# M2Sxxx register map
Vendor: Microsemi; Series: SmartFusion2; File version: 2.0.32
CPU: CM3 r2p1, little endian, MPU, no FPU, 4 interrupt priority bits
Registers are 32-bit, read-write, no defined reset value unless marked. A register's access mark holds for its fields unless they carry their own. Offsets are from the block's base; [hi:lo] are bit positions; {n}, {i} and the like mark numbered series.

## HPDMA — No description provided for this peripheral
Base 0x40014000
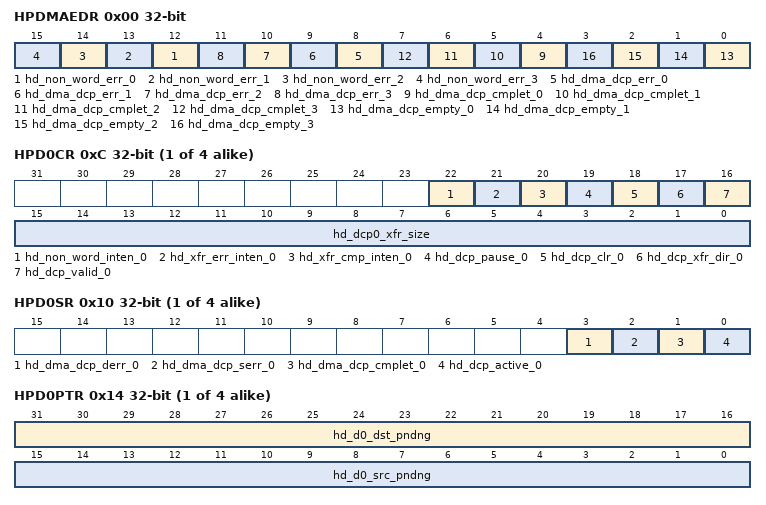
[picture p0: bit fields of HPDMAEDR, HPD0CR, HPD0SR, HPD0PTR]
0x00 HPDMAEDR — No description provided for this register
  [n+12] hd_non_word_err_{n} ro (n=0..3) — No description provided for this field
  [n+8] hd_dma_dcp_err_{n} ro (n=0..3) — No description provided for this field
  [n+4] hd_dma_dcp_cmplet_{n} ro (n=0..3) — No description provided for this field
  [n] hd_dma_dcp_empty_{n} ro (n=0..3) — No description provided for this field
{0x4+0x14*i} HPD{i}SAR (i=0..3) — No description provided for this register
  [31:0] hd_dcp{i}_src_adrs — No description provided for this field
{0x8+0x14*i} HPD{i}DAR (i=0..3) — No description provided for this register
  [31:0] hd_dcp{i}_dst_adrs — No description provided for this field
{0xC+0x14*i} HPD{i}CR (i=0..3) — No description provided for this register
  [22] hd_non_word_inten_{i} — No description provided for this field
  [21] hd_xfr_err_inten_{i} — No description provided for this field
  [20] hd_xfr_cmp_inten_{i} — No description provided for this field
  [19] hd_dcp_pause_{i} — No description provided for this field
  [18] hd_dcp_clr_{i} — No description provided for this field
  [17] hd_dcp_xfr_dir_{i} — No description provided for this field
  [16] hd_dcp_valid_{i} — No description provided for this field
  [15:0] hd_dcp{i}_xfr_size — No description provided for this field
{0x10+0x14*i} HPD{i}SR (i=0..3) — No description provided for this register
  [3] hd_dma_dcp_derr_{i} ro — No description provided for this field
  [2] hd_dma_dcp_serr_{i} ro — No description provided for this field
  [1] hd_dma_dcp_cmplet_{i} ro — No description provided for this field
  [0] hd_dcp_active_{i} ro — No description provided for this field
{0x14+0x14*i} HPD{i}PTR (i=0..3) — No description provided for this register
  [31:16] hd_d{i}_dst_pndng ro — No description provided for this field
  [15:0] hd_d{i}_src_pndng ro — No description provided for this field
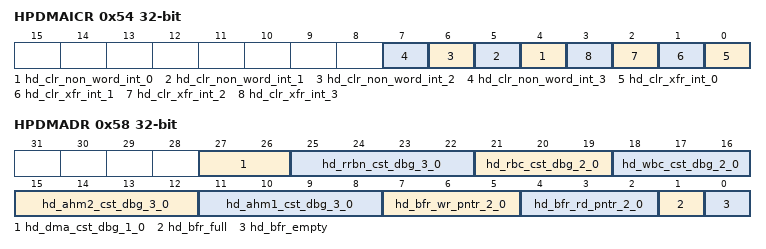
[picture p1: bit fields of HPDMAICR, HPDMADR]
0x54 HPDMAICR — No description provided for this register
  [n+4] hd_clr_non_word_int_{n} wo (n=0..3) — No description provided for this field
  [n] hd_clr_xfr_int_{n} wo (n=0..3) — No description provided for this field
0x58 HPDMADR — No description provided for this register
  [27:26] hd_dma_cst_dbg_1_0 ro — No description provided for this field
  [25:22] hd_rrbn_cst_dbg_3_0 ro — No description provided for this field
  [21:19] hd_rbc_cst_dbg_2_0 ro — No description provided for this field
  [18:16] hd_wbc_cst_dbg_2_0 ro — No description provided for this field
  [15:12] hd_ahm2_cst_dbg_3_0 ro — No description provided for this field
  [11:8] hd_ahm1_cst_dbg_3_0 ro — No description provided for this field
  [7:5] hd_bfr_wr_pntr_2_0 ro — No description provided for this field
  [4:2] hd_bfr_rd_pntr_2_0 ro — No description provided for this field
  [1] hd_bfr_full ro — No description provided for this field
  [0] hd_bfr_empty ro — No description provided for this field

## PDMA — No description provided for this peripheral
Base 0x40003000
0x00 RATIO_HIGH_LOW_Register — No description provided for this register
  [7:0] RATIOHILO — No description provided for this field
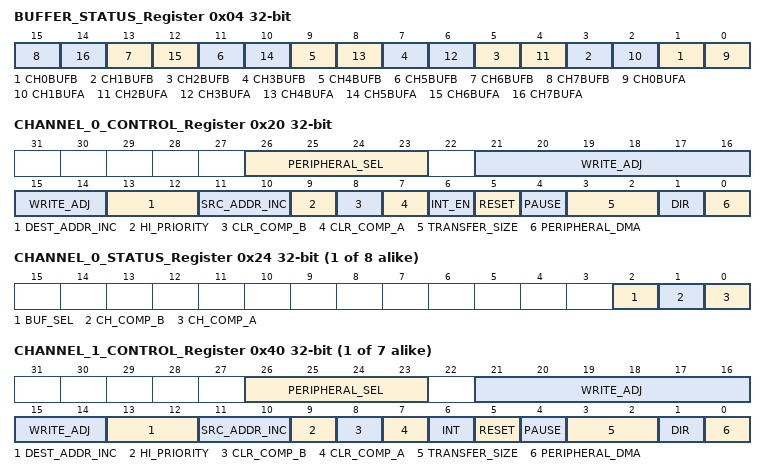
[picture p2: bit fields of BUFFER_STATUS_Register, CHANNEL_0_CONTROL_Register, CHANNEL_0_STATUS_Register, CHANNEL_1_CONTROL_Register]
0x04 BUFFER_STATUS_Register — No description provided for this register
  [2n+1] CH{n}BUFB ro (n=0..7) — No description provided for this field
  [2n] CH{n}BUFA ro (n=0..7) — No description provided for this field
0x20 CHANNEL_0_CONTROL_Register — No description provided for this register
  [26:23] PERIPHERAL_SEL — No description provided for this field
  [21:14] WRITE_ADJ — No description provided for this field
  [13:12] DEST_ADDR_INC — No description provided for this field
  [11:10] SRC_ADDR_INC — No description provided for this field
  [9] HI_PRIORITY — No description provided for this field
  [8] CLR_COMP_B — No description provided for this field
  [7] CLR_COMP_A — No description provided for this field
  [6] INT_EN — No description provided for this field
  [5] RESET — No description provided for this field
  [4] PAUSE — No description provided for this field
  [3:2] TRANSFER_SIZE — No description provided for this field
  [1] DIR — No description provided for this field
  [0] PERIPHERAL_DMA — No description provided for this field
{0x24+0x20*i} CHANNEL_{i}_STATUS_Register (i=0..7) — No description provided for this register
  [2] BUF_SEL ro — No description provided for this field
  [1] CH_COMP_B ro — No description provided for this field
  [0] CH_COMP_A ro — No description provided for this field
{0x28+0x20*i} CHANNEL_{i}_BUFFER_A_SRC_ADDR_Register (i=0..7) — No description provided for this register
  [31:0] BUF_A_SRC — No description provided for this field
{0x2C+0x20*i} CHANNEL_{i}_BUFFER_A_DST_ADDR_Register (i=0..7) — No description provided for this register
  [31:0] BUF_A_DST — No description provided for this field
{0x30+0x20*i} CHANNEL_{i}_BUFFER_A_TRANSFER_COUNT_Register (i=0..7) — No description provided for this register
  [15:0] BUF_A_COUNT — No description provided for this field
{0x34+0x20*i} CHANNEL_{i}_BUFFER_B_SRC_ADDR_Register (i=0..7) — No description provided for this register
  [31:0] BUF_B_SRC — No description provided for this field
{0x38+0x20*i} CHANNEL_{i}_BUFFER_B_DST_ADDR_Register (i=0..7) — No description provided for this register
  [31:0] BUF_B_DST — No description provided for this field
{0x3C+0x20*i} CHANNEL_{i}_BUFFER_B_TRANSFER_COUNT_Register (i=0..7) — No description provided for this register
  [15:0] BUF_B_COUNT — No description provided for this field
{0x20+0x20*i} CHANNEL_{i}_CONTROL_Register (i=1..7) — No description provided for this register
  [26:23] PERIPHERAL_SEL — No description provided for this field
  [21:14] WRITE_ADJ — No description provided for this field
  [13:12] DEST_ADDR_INC — No description provided for this field
  [11:10] SRC_ADDR_INC — No description provided for this field
  [9] HI_PRIORITY — No description provided for this field
  [8] CLR_COMP_B — No description provided for this field
  [7] CLR_COMP_A — No description provided for this field
  [6] INT — No description provided for this field
  [5] RESET — No description provided for this field
  [4] PAUSE — No description provided for this field
  [3:2] TRANSFER_SIZE — No description provided for this field
  [1] DIR — No description provided for this field
  [0] PERIPHERAL_DMA — No description provided for this field
